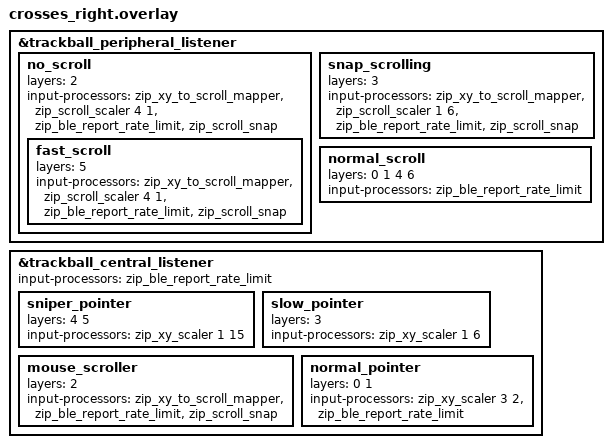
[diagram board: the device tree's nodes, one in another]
#include "../../gggw-zmk-keebs/boards/shields/crosses/crosses.dtsi"

&trackball_peripheral_listener {
  status = "okay";
  no_scroll {
    fast_scroll {
    layers = <5>;
    input-processors
      = <&zip_xy_to_scroll_mapper>/
      , <&zip_scroll_scaler 4 1>
      , <&zip_ble_report_rate_limit>
	  , <&zip_scroll_snap>              //  snap to a direction for macos
	  ;
  };
    layers = <2>;
    input-processors 
      = <&zip_xy_to_scroll_mapper>
      , <&zip_scroll_scaler 4 1>
      , <&zip_ble_report_rate_limit>
	  , <&zip_scroll_snap>              //  snap to a direction for macos
	  ;
  };
  snap_scrolling {
	layers = <3>;
    input-processors
      = <&zip_xy_to_scroll_mapper>
      , <&zip_scroll_scaler 1 6>
      , <&zip_ble_report_rate_limit>
	  , <&zip_scroll_snap>              //  snap to a direction for macos
	  ;
  };
  	normal_scroll {
    layers = <0 1 4 6>;  /* list every layer where mouse should work */
    input-processors = <&zip_ble_report_rate_limit>;
  };
};



&trackball_central_listener {
	input-processors = <&zip_ble_report_rate_limit>;

    sniper_pointer: sniper_pointer {
		layers           = <4 5>;
		input-processors =
				<&zip_xy_scaler 1 15>           // Scales the scroll speed
			//,<&zip_xy_to_scroll_mapper>      // Converts XY movement to scroll events 
			//,<&zip_scroll_snap>              //  snap to a direction for macos
			//,<&zip_scroll_transform (INPUT_TRANSFORM_Y_INVERT)> // Inverts the scroll direction
			;
		};

   	slow_pointer: slow_pointer{
	    layers = <3>;
	    input-processors =
	        <&zip_xy_scaler 1 6> //1 6 
		//,	<&zip_xy_to_scroll_mapper>	      
		//, <&zip_ble_report_rate_limit>
		;
	  };

	mouse_scroller: mouse_scroller{
	    layers = <2>;
	    input-processors =
	    //    <&zip_xy_scaler 1 6> //1 6 
			<&zip_xy_to_scroll_mapper>	      
		, <&zip_ble_report_rate_limit>
		, <&zip_scroll_snap>              //  snap to a direction for macos
		;
	  };

	normal_pointer: normal_pointer {
			layers           = <0 1>;
			input-processors = 
				<&zip_xy_scaler 3 2>
			, 	<&zip_ble_report_rate_limit>
			;
		};

};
